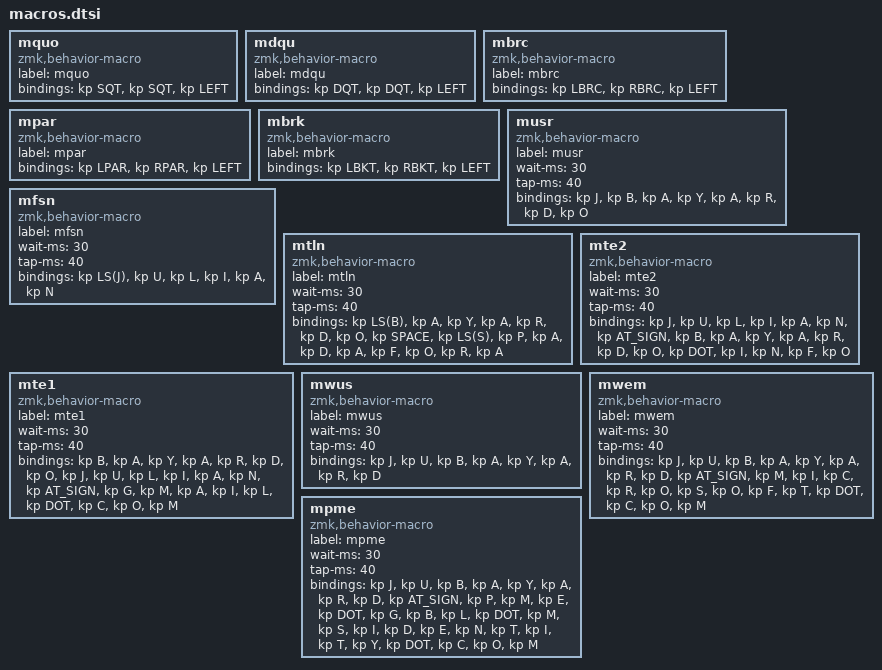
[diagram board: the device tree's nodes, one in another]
mquo: mquo {
    compatible = "zmk,behavior-macro";
    label = "mquo";
    #binding-cells = <0>;
    bindings = <&kp SQT>, <&kp SQT>, <&kp LEFT>;
};

mdqu: mdqu {
    compatible = "zmk,behavior-macro";
    label = "mdqu";
    #binding-cells = <0>;
    bindings = <&kp DQT>, <&kp DQT>, <&kp LEFT>;
};

mbrc: mbrc {
    compatible = "zmk,behavior-macro";
    label = "mbrc";
    #binding-cells = <0>;
    bindings = <&kp LBRC>, <&kp RBRC>, <&kp LEFT>;
};

mpar: mpar {
    compatible = "zmk,behavior-macro";
    label = "mpar";
    #binding-cells = <0>;
    bindings = <&kp LPAR>, <&kp RPAR>, <&kp LEFT>;
};

mbrk: mbrk {
    compatible = "zmk,behavior-macro";
    label = "mbrk";
    #binding-cells = <0>;
    bindings = <&kp LBKT>, <&kp RBKT>, <&kp LEFT>;
};

musr: musr {
    compatible = "zmk,behavior-macro";
    label = "musr";
    #binding-cells = <0>;
    wait-ms = <30>;
    tap-ms = <40>;
    bindings = <
        &kp J &kp B &kp A &kp Y &kp A &kp R &kp D &kp O
    >;
};

mfsn: mfsn {
    compatible = "zmk,behavior-macro";
    label = "mfsn";
    #binding-cells = <0>;
    wait-ms = <30>;
    tap-ms = <40>;
    bindings = <
        &kp LS(J) &kp U &kp L &kp I &kp A &kp N
    >;
};

mtln: mtln {
    compatible = "zmk,behavior-macro";
    label = "mtln";
    #binding-cells = <0>;
    wait-ms = <30>;
    tap-ms = <40>;
    bindings = <
        &kp LS(B) &kp A &kp Y &kp A &kp R &kp D &kp O
        &kp SPACE
        &kp LS(S) &kp P &kp A &kp D &kp A &kp F &kp O &kp R &kp A
    >;
};

mte2: mte2 {
    compatible = "zmk,behavior-macro";
    label = "mte2";
    #binding-cells = <0>;
    wait-ms = <30>;
    tap-ms = <40>;
    bindings = <
        &kp J &kp U &kp L &kp I &kp A &kp N
        &kp AT_SIGN
        &kp B &kp A &kp Y &kp A &kp R &kp D &kp O
        &kp DOT
        &kp I &kp N &kp F &kp O
    >;
};

mte1: mte1 {
    compatible = "zmk,behavior-macro";
    label = "mte1";
    #binding-cells = <0>;
    wait-ms = <30>;
    tap-ms = <40>;
    bindings = <
        &kp B &kp A &kp Y &kp A &kp R &kp D &kp O
        &kp J &kp U &kp L &kp I &kp A &kp N
        &kp AT_SIGN
        &kp G &kp M &kp A &kp I &kp L
        &kp DOT
        &kp C &kp O &kp M
    >;
};

mwus: mwus {
    compatible = "zmk,behavior-macro";
    label = "mwus";
    #binding-cells = <0>;
    wait-ms = <30>;
    tap-ms = <40>;
    bindings = <
        &kp J &kp U &kp B &kp A &kp Y &kp A &kp R &kp D
    >;
};

mwem: mwem {
    compatible = "zmk,behavior-macro";
    label = "mwem";
    #binding-cells = <0>;
    wait-ms = <30>;
    tap-ms = <40>;
    bindings = <
        &kp J &kp U &kp B &kp A &kp Y &kp A &kp R &kp D
        &kp AT_SIGN
        &kp M &kp I &kp C &kp R &kp O &kp S &kp O &kp F &kp T
        &kp DOT
        &kp C &kp O &kp M
    >;
};

mpme: mpme {
    compatible = "zmk,behavior-macro";
    label = "mpme";
    #binding-cells = <0>;
    wait-ms = <30>;
    tap-ms = <40>;
    bindings = <
        &kp J &kp U &kp B &kp A &kp Y &kp A &kp R &kp D
        &kp AT_SIGN
        &kp P &kp M &kp E
        &kp DOT
        &kp G &kp B &kp L
        &kp DOT
        &kp M &kp S &kp I &kp D &kp E &kp N &kp T &kp I &kp T &kp Y
        &kp DOT
        &kp C &kp O &kp M
    >;
};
